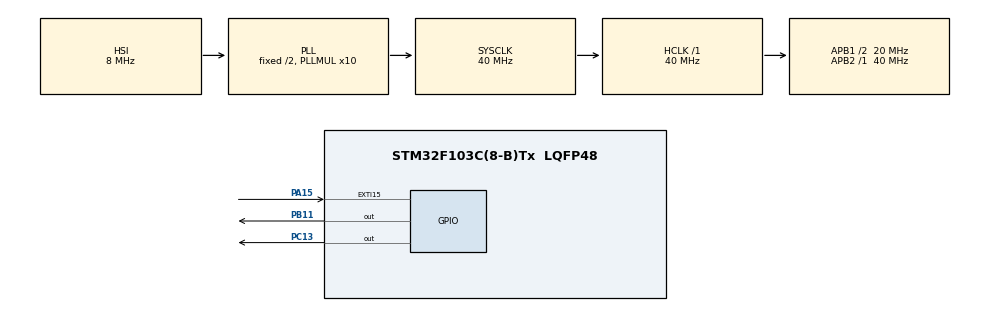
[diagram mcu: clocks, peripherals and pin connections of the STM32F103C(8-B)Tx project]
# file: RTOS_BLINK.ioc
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FREERTOS.BinarySemaphores01=myBinarySem01,Dynamic,NULL
FREERTOS.Tasks01=myTask01,0,128,StartDefaultTask,Default,NULL,Dynamic,NULL,NULL;myTask02,-3,128,StartTask02,Default,NULL,Dynamic,NULL,NULL
FREERTOS.configUSE_NEWLIB_REENTRANT=1
Mcu.Family=STM32F1
Mcu.Name=STM32F103C(8-B)Tx
Mcu.Package=LQFP48
NVIC.EXTI15_10_IRQn=true\:5\:0\:false\:false\:true\:true\:true\:true\:true
NVIC.PriorityGroup=NVIC_PRIORITYGROUP_4
NVIC.RCC_IRQn=true\:5\:0\:false\:false\:true\:true\:true\:false\:true
NVIC.TIM3_IRQn=true\:15\:0\:false\:false\:true\:false\:false\:true\:true
NVIC.TimeBase=TIM3_IRQn
NVIC.TimeBaseIP=TIM3
PA13.Mode=Serial_Wire
PA13.Signal=SYS_JTMS-SWDIO
PA14.Mode=Serial_Wire
PA14.Signal=SYS_JTCK-SWCLK
PA15.GPIO_ModeDefaultEXTI=GPIO_MODE_IT_FALLING
PA15.GPIO_PuPd=GPIO_PULLUP
PA15.Signal=GPXTI15
PB11.Signal=GPIO_Output
PC13-TAMPER-RTC.PinState=GPIO_PIN_SET
PC13-TAMPER-RTC.Signal=GPIO_Output
PD0-OSC_IN.Mode=HSE-External-Oscillator
PD0-OSC_IN.Signal=RCC_OSC_IN
PD1-OSC_OUT.Mode=HSE-External-Oscillator
PD1-OSC_OUT.Signal=RCC_OSC_OUT
ProjectManager.HeapSize=0x200
ProjectManager.StackSize=0x400
ProjectManager.TargetToolchain=STM32CubeIDE
RCC.AHBFreq_Value=40000000
RCC.APB1CLKDivider=RCC_HCLK_DIV2
RCC.APB1Freq_Value=20000000
RCC.APB1TimFreq_Value=40000000
RCC.APB2Freq_Value=40000000
RCC.APB2TimFreq_Value=40000000
RCC.HCLKFreq_Value=40000000
RCC.PLLMUL=RCC_PLL_MUL10
RCC.SYSCLKFreq_VALUE=40000000
RCC.SYSCLKSource=RCC_SYSCLKSOURCE_PLLCLK
RCC.USBFreq_Value=40000000
VP_FREERTOS_VS_CMSIS_V1.Mode=CMSIS_V1
VP_SYS_VS_tim3.Mode=TIM3
board=custom

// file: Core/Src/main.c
/* USER CODE BEGIN Header */
/**
  ******************************************************************************
  * @file           : main.c
  * @brief          : Main program body
  ******************************************************************************
  * @attention
  *
  * Copyright (c) 2024 STMicroelectronics.
  * All rights reserved.
  *
  * This software is licensed under terms that can be found in the LICENSE file
  * in the root directory of this software component.
  * If no LICENSE file comes with this software, it is provided AS-IS.
  *
  ******************************************************************************
  */
/* USER CODE END Header */
#include "main.h"
#include "cmsis_os.h"

osThreadId myTask01Handle;
osThreadId myTask02Handle;
osSemaphoreId myBinarySem01Handle;

void SystemClock_Config(void);
static void MX_GPIO_Init(void);
void StartDefaultTask(void const * argument);
void StartTask02(void const * argument);

int main(void)
{

  /* MCU Configuration--------------------------------------------------------*/

  /* Reset of all peripherals, Initializes the Flash interface and the Systick. */
  HAL_Init();

  /* Configure the system clock */
  SystemClock_Config();

  /* Initialize all configured peripherals */
  MX_GPIO_Init();

  /* Create the semaphores(s) */
  /* definition and creation of myBinarySem01 */
  osSemaphoreDef(myBinarySem01);
  myBinarySem01Handle = osSemaphoreCreate(osSemaphore(myBinarySem01), 1);

  /* Create the thread(s) */
  /* definition and creation of myTask01 */
  osThreadDef(myTask01, StartDefaultTask, osPriorityNormal, 0, 128);
  myTask01Handle = osThreadCreate(osThread(myTask01), NULL);

  /* definition and creation of myTask02 */
  osThreadDef(myTask02, StartTask02, osPriorityIdle, 0, 128);
  myTask02Handle = osThreadCreate(osThread(myTask02), NULL);

  /* Start scheduler */
  osKernelStart();

  /* We should never get here as control is now taken by the scheduler */
  /* Infinite loop */
  while (1)
  {

  }
}

void SystemClock_Config(void)
{
  RCC_OscInitTypeDef RCC_OscInitStruct = {0};
  RCC_ClkInitTypeDef RCC_ClkInitStruct = {0};

  /** Initializes the RCC Oscillators according to the specified parameters
  * in the RCC_OscInitTypeDef structure.
  */
  RCC_OscInitStruct.OscillatorType = RCC_OSCILLATORTYPE_HSI;
  RCC_OscInitStruct.HSIState = RCC_HSI_ON;
  RCC_OscInitStruct.HSICalibrationValue = RCC_HSICALIBRATION_DEFAULT;
  RCC_OscInitStruct.PLL.PLLState = RCC_PLL_ON;
  RCC_OscInitStruct.PLL.PLLSource = RCC_PLLSOURCE_HSI_DIV2;
  RCC_OscInitStruct.PLL.PLLMUL = RCC_PLL_MUL10;
  if (HAL_RCC_OscConfig(&RCC_OscInitStruct) != HAL_OK)
  {
    Error_Handler();
  }

  /** Initializes the CPU, AHB and APB buses clocks
  */
  RCC_ClkInitStruct.ClockType = RCC_CLOCKTYPE_HCLK|RCC_CLOCKTYPE_SYSCLK
                              |RCC_CLOCKTYPE_PCLK1|RCC_CLOCKTYPE_PCLK2;
  RCC_ClkInitStruct.SYSCLKSource = RCC_SYSCLKSOURCE_PLLCLK;
  RCC_ClkInitStruct.AHBCLKDivider = RCC_SYSCLK_DIV1;
  RCC_ClkInitStruct.APB1CLKDivider = RCC_HCLK_DIV2;
  RCC_ClkInitStruct.APB2CLKDivider = RCC_HCLK_DIV1;

  if (HAL_RCC_ClockConfig(&RCC_ClkInitStruct, FLASH_LATENCY_1) != HAL_OK)
  {
    Error_Handler();
  }
}

static void MX_GPIO_Init(void)
{
  GPIO_InitTypeDef GPIO_InitStruct = {0};

  /* GPIO Ports Clock Enable */
  __HAL_RCC_GPIOC_CLK_ENABLE();
  __HAL_RCC_GPIOD_CLK_ENABLE();
  __HAL_RCC_GPIOB_CLK_ENABLE();
  __HAL_RCC_GPIOA_CLK_ENABLE();

  /*Configure GPIO pin Output Level */
  HAL_GPIO_WritePin(GPIOC, GPIO_PIN_13, GPIO_PIN_SET);

  /*Configure GPIO pin Output Level */
  HAL_GPIO_WritePin(GPIOB, GPIO_PIN_11, GPIO_PIN_RESET);

  /*Configure GPIO pin : PC13 */
  GPIO_InitStruct.Pin = GPIO_PIN_13;
  GPIO_InitStruct.Mode = GPIO_MODE_OUTPUT_PP;
  GPIO_InitStruct.Pull = GPIO_NOPULL;
  GPIO_InitStruct.Speed = GPIO_SPEED_FREQ_LOW;
  HAL_GPIO_Init(GPIOC, &GPIO_InitStruct);

  /*Configure GPIO pin : PB11 */
  GPIO_InitStruct.Pin = GPIO_PIN_11;
  GPIO_InitStruct.Mode = GPIO_MODE_OUTPUT_PP;
  GPIO_InitStruct.Pull = GPIO_NOPULL;
  GPIO_InitStruct.Speed = GPIO_SPEED_FREQ_LOW;
  HAL_GPIO_Init(GPIOB, &GPIO_InitStruct);

  /*Configure GPIO pin : PA15 */
  GPIO_InitStruct.Pin = GPIO_PIN_15;
  GPIO_InitStruct.Mode = GPIO_MODE_IT_FALLING;
  GPIO_InitStruct.Pull = GPIO_PULLUP;
  HAL_GPIO_Init(GPIOA, &GPIO_InitStruct);

  /* EXTI interrupt init*/
  HAL_NVIC_SetPriority(EXTI15_10_IRQn, 5, 0);
  HAL_NVIC_EnableIRQ(EXTI15_10_IRQn);

}

/* USER CODE BEGIN 4 */
void HAL_GPIO_EXTI_Callback(uint16_t GPIO_Pin)
{
  if(GPIO_Pin == GPIO_PIN_15)
  {

    HAL_GPIO_TogglePin(GPIOB, GPIO_PIN_11);

  }
  else
  {
      __NOP();
  }
}
/* USER CODE END 4 */

void StartDefaultTask(void const * argument)
{
  /* USER CODE BEGIN 5 */
  /* Infinite loop */
  for(;;)
  {
	  osSemaphoreWait(myBinarySem01Handle, osWaitForever);
	  HAL_GPIO_TogglePin(GPIOB, GPIO_PIN_11);
	  osDelay(2000);
	  osSemaphoreRelease (myBinarySem01Handle);

	  osDelay(1);
  }
  /* USER CODE END 5 */
}

void StartTask02(void const * argument)
{
  /* USER CODE BEGIN StartTask02 */
  /* Infinite loop */
  for(;;)
  {
	  osSemaphoreWait(myBinarySem01Handle, osWaitForever);
	  HAL_GPIO_TogglePin(GPIOB, GPIO_PIN_11);
	  osDelay(2000);
	  osSemaphoreRelease (myBinarySem01Handle);

	  osDelay(1);

  }
  /* USER CODE END StartTask02 */
}

void HAL_TIM_PeriodElapsedCallback(TIM_HandleTypeDef *htim)
{
  if (htim->Instance == TIM3) {
    HAL_IncTick();
  }
}

void Error_Handler(void)
{
  __disable_irq();
  while (1)
  {
  }
}
